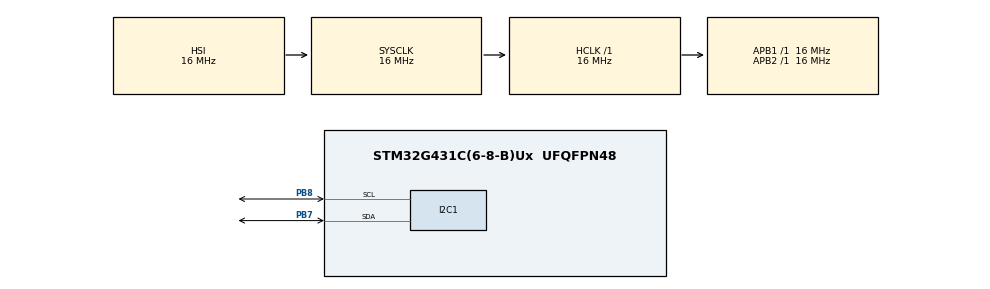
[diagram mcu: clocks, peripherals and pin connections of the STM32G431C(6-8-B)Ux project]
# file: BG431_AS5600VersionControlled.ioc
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I2C1.Timing=0x00503D58
Mcu.Family=STM32G4
Mcu.Name=STM32G431C(6-8-B)Ux
Mcu.Package=UFQFPN48
NVIC.PriorityGroup=NVIC_PRIORITYGROUP_4
PB7.Mode=I2C
PB7.Signal=I2C1_SDA
PB8-BOOT0.Mode=I2C
PB8-BOOT0.Signal=I2C1_SCL
ProjectManager.HeapSize=0x200
ProjectManager.StackSize=0x400
ProjectManager.TargetToolchain=STM32CubeIDE
RCC.AHBFreq_Value=16000000
RCC.APB1Freq_Value=16000000
RCC.APB1TimFreq_Value=16000000
RCC.APB2Freq_Value=16000000
RCC.APB2TimFreq_Value=16000000
RCC.CortexFreq_Value=16000000
RCC.EXTERNAL_CLOCK_VALUE=12288000
RCC.HCLKFreq_Value=16000000
RCC.HSE_VALUE=8000000
RCC.HSI48_VALUE=48000000
RCC.HSI_VALUE=16000000
RCC.LSE_VALUE=32768
RCC.SYSCLKFreq_VALUE=16000000
RCC.USBFreq_Value=64000000
RCC.VCOOutputFreq_Value=128000000
VP_SYS_VS_DBSignals.Mode=DisableDeadBatterySignals
board=custom

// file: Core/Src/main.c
/* USER CODE BEGIN Header */
/**
  ******************************************************************************
  * @file           : main.c
  * @brief          : Main program body
  ******************************************************************************
  * @attention
  *
  * Copyright (c) 2025 STMicroelectronics.
  * All rights reserved.
  *
  * This software is licensed under terms that can be found in the LICENSE file
  * in the root directory of this software component.
  * If no LICENSE file comes with this software, it is provided AS-IS.
  *
  ******************************************************************************
  */
/* USER CODE END Header */
#include "main.h"

/* USER CODE BEGIN PD */

// AS5600 I2C address (7-bit)
#define AS5600_ADDR         (0x36 << 1)   // shift left because HAL uses 8-bit address

#define AS5600_REG_RAW_ANGLE_HIGH  0x0C
#define AS5600_REG_RAW_ANGLE_LOW   0x0D  //  0x0C = high byte, 0x0D = low byte

float angle;

/* USER CODE END PD */

I2C_HandleTypeDef hi2c1;

void SystemClock_Config(void);
static void MX_GPIO_Init(void);
static void MX_I2C1_Init(void);

/* USER CODE BEGIN 0 */

uint16_t read_raw_angle(void)
{
    uint8_t buf[2];
    HAL_StatusTypeDef status;

    // Read 2 bytes from RAW_ANGLE register
    status = HAL_I2C_Mem_Read(&hi2c1,
                              AS5600_ADDR,
                              AS5600_REG_RAW_ANGLE_HIGH,
                              I2C_MEMADD_SIZE_8BIT,
                              buf, 2,
                              HAL_MAX_DELAY);
    if (status != HAL_OK) {
        // handle error (timeout, etc.)
        return 0;
    }

    // combine MSB and LSB into 12-bit value
    uint16_t raw = ((uint16_t)buf[0] << 8) | buf[1];
    // raw is 16-bit right now, but actual value is 12-bit (0–4095)
    raw &= 0x0FFF;
    return raw;
}

float raw_to_degrees(uint16_t raw)
{
    // 0–4095 maps to 0–360°
    return (raw * 360.0f) / 4096.0f;
}

/* USER CODE END 0 */

int main(void)
{

  /* MCU Configuration--------------------------------------------------------*/

  /* Reset of all peripherals, Initializes the Flash interface and the Systick. */
  HAL_Init();

  /* Configure the system clock */
  SystemClock_Config();

  /* Initialize all configured peripherals */
  MX_GPIO_Init();
  MX_I2C1_Init();

  /* Infinite loop */
  while (1)
  {

      uint16_t raw = read_raw_angle();
      angle = raw_to_degrees(raw);

      HAL_Delay(10); // read every 10ms

  }
}

void SystemClock_Config(void)
{
  RCC_OscInitTypeDef RCC_OscInitStruct = {0};
  RCC_ClkInitTypeDef RCC_ClkInitStruct = {0};

  /** Configure the main internal regulator output voltage
  */
  HAL_PWREx_ControlVoltageScaling(PWR_REGULATOR_VOLTAGE_SCALE1);

  /** Initializes the RCC Oscillators according to the specified parameters
  * in the RCC_OscInitTypeDef structure.
  */
  RCC_OscInitStruct.OscillatorType = RCC_OSCILLATORTYPE_HSI;
  RCC_OscInitStruct.HSIState = RCC_HSI_ON;
  RCC_OscInitStruct.HSICalibrationValue = RCC_HSICALIBRATION_DEFAULT;
  RCC_OscInitStruct.PLL.PLLState = RCC_PLL_NONE;
  if (HAL_RCC_OscConfig(&RCC_OscInitStruct) != HAL_OK)
  {
    Error_Handler();
  }

  /** Initializes the CPU, AHB and APB buses clocks
  */
  RCC_ClkInitStruct.ClockType = RCC_CLOCKTYPE_HCLK|RCC_CLOCKTYPE_SYSCLK
                              |RCC_CLOCKTYPE_PCLK1|RCC_CLOCKTYPE_PCLK2;
  RCC_ClkInitStruct.SYSCLKSource = RCC_SYSCLKSOURCE_HSI;
  RCC_ClkInitStruct.AHBCLKDivider = RCC_SYSCLK_DIV1;
  RCC_ClkInitStruct.APB1CLKDivider = RCC_HCLK_DIV1;
  RCC_ClkInitStruct.APB2CLKDivider = RCC_HCLK_DIV1;

  if (HAL_RCC_ClockConfig(&RCC_ClkInitStruct, FLASH_LATENCY_0) != HAL_OK)
  {
    Error_Handler();
  }
}

static void MX_I2C1_Init(void)
{

  hi2c1.Instance = I2C1;
  hi2c1.Init.Timing = 0x00503D58;
  hi2c1.Init.OwnAddress1 = 0;
  hi2c1.Init.AddressingMode = I2C_ADDRESSINGMODE_7BIT;
  hi2c1.Init.DualAddressMode = I2C_DUALADDRESS_DISABLE;
  hi2c1.Init.OwnAddress2 = 0;
  hi2c1.Init.OwnAddress2Masks = I2C_OA2_NOMASK;
  hi2c1.Init.GeneralCallMode = I2C_GENERALCALL_DISABLE;
  hi2c1.Init.NoStretchMode = I2C_NOSTRETCH_DISABLE;
  if (HAL_I2C_Init(&hi2c1) != HAL_OK)
  {
    Error_Handler();
  }

  /** Configure Analogue filter
  */
  if (HAL_I2CEx_ConfigAnalogFilter(&hi2c1, I2C_ANALOGFILTER_ENABLE) != HAL_OK)
  {
    Error_Handler();
  }

  /** Configure Digital filter
  */
  if (HAL_I2CEx_ConfigDigitalFilter(&hi2c1, 0) != HAL_OK)
  {
    Error_Handler();
  }

}

static void MX_GPIO_Init(void)
{

  /* GPIO Ports Clock Enable */
  __HAL_RCC_GPIOB_CLK_ENABLE();

}

void Error_Handler(void)
{
  __disable_irq();
  while (1)
  {
  }
}
